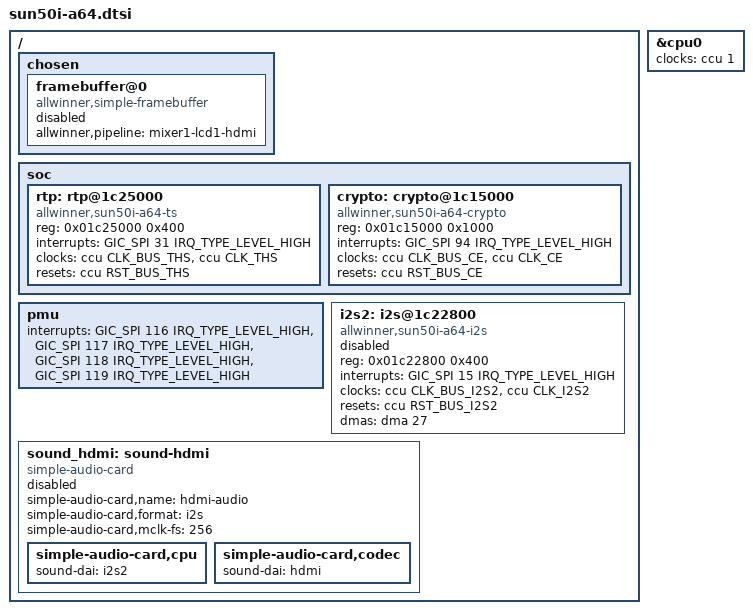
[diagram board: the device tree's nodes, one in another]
/* $NetBSD: sun50i-a64.dtsi,v 1.14 2019/12/09 04:40:50 riastradh Exp $ */

/*-
 * Copyright (c) 2017 Jared McNeill <jmcneill@invisible.ca>
 * All rights reserved.
 *
 * Redistribution and use in source and binary forms, with or without
 * modification, are permitted provided that the following conditions
 * are met:
 * 1. Redistributions of source code must retain the above copyright
 *    notice, this list of conditions and the following disclaimer.
 * 2. Redistributions in binary form must reproduce the above copyright
 *    notice, this list of conditions and the following disclaimer in the
 *    documentation and/or other materials provided with the distribution.
 *
 * THIS SOFTWARE IS PROVIDED BY THE AUTHOR ``AS IS'' AND ANY EXPRESS OR
 * IMPLIED WARRANTIES, INCLUDING, BUT NOT LIMITED TO, THE IMPLIED WARRANTIES
 * OF MERCHANTABILITY AND FITNESS FOR A PARTICULAR PURPOSE ARE DISCLAIMED.
 * IN NO EVENT SHALL THE AUTHOR BE LIABLE FOR ANY DIRECT, INDIRECT,
 * INCIDENTAL, SPECIAL, EXEMPLARY, OR CONSEQUENTIAL DAMAGES (INCLUDING,
 * BUT NOT LIMITED TO, PROCUREMENT OF SUBSTITUTE GOODS OR SERVICES;
 * LOSS OF USE, DATA, OR PROFITS; OR BUSINESS INTERRUPTION) HOWEVER CAUSED
 * AND ON ANY THEORY OF LIABILITY, WHETHER IN CONTRACT, STRICT LIABILITY,
 * OR TORT (INCLUDING NEGLIGENCE OR OTHERWISE) ARISING IN ANY WAY
 * OUT OF THE USE OF THIS SOFTWARE, EVEN IF ADVISED OF THE POSSIBILITY OF
 * SUCH DAMAGE.
 */

/ {
	chosen {
		#address-cells = <1>;
		#size-cells = <1>;
		ranges;

		framebuffer@0 {
			compatible = "allwinner,simple-framebuffer",
				     "simple-framebuffer";
			allwinner,pipeline = "mixer1-lcd1-hdmi";
			status = "disabled";
		};
	};

	soc {
		rtp: rtp@1c25000 {
			compatible = "allwinner,sun50i-a64-ts";
			reg = <0x01c25000 0x400>;
			interrupts = <GIC_SPI 31 IRQ_TYPE_LEVEL_HIGH>;
			clocks = <&ccu CLK_BUS_THS>, <&ccu CLK_THS>;
			clock-names = "ahb", "ths";
			resets = <&ccu RST_BUS_THS>;
			#thermal-sensor-cells = <0>;
		};

		crypto: crypto@1c15000 {
			compatible = "allwinner,sun50i-a64-crypto";
			reg = <0x01c15000 0x1000>;
			interrupts = <GIC_SPI 94 IRQ_TYPE_LEVEL_HIGH>;
			clocks = <&ccu CLK_BUS_CE>, <&ccu CLK_CE>;
			clock-names = "bus", "mod";
			resets = <&ccu RST_BUS_CE>;
		};
	};

	/* PMU interrupt numbers are wrong in mainline dts */
	pmu {
		interrupts = <GIC_SPI 116 IRQ_TYPE_LEVEL_HIGH>,
			     <GIC_SPI 117 IRQ_TYPE_LEVEL_HIGH>,
			     <GIC_SPI 118 IRQ_TYPE_LEVEL_HIGH>,
			     <GIC_SPI 119 IRQ_TYPE_LEVEL_HIGH>;
	};

	i2s2: i2s@1c22800 {
		#sound-dai-cells = <0>;
		compatible = "allwinner,sun50i-a64-i2s",
			     "allwinner,sun8i-h3-i2s";
		reg = <0x01c22800 0x400>;
		interrupts = <GIC_SPI 15 IRQ_TYPE_LEVEL_HIGH>;
		clocks = <&ccu CLK_BUS_I2S2>, <&ccu CLK_I2S2>;
		clock-names = "apb", "mod";
		resets = <&ccu RST_BUS_I2S2>;
		dma-names = "tx";
		dmas = <&dma 27>;
		status = "disabled";
	};

	sound_hdmi: sound-hdmi {
		compatible = "simple-audio-card";
		simple-audio-card,name = "hdmi-audio";
		simple-audio-card,format = "i2s";
		simple-audio-card,mclk-fs = <256>;
		status = "disabled";

		simple-audio-card,cpu {
			sound-dai = <&i2s2>;
		};

		simple-audio-card,codec {
			sound-dai = <&hdmi>;
		};
	};
};

&cpu0 {
	clocks = <&ccu 1>; /* 1=CLK_PLL_CPUX */
};
